# APM32F423 register map
File version: 1.0
CPU: CM4 r1p0, little endian, no MPU, no FPU, 4 interrupt priority bits
Registers are 32-bit, read-write, reset 0x0 unless marked. A register's access mark holds for its fields unless they carry their own. Offsets are from the block's base; [hi:lo] are bit positions.

## FMC — Flash memory controller
Base 0x40023C00
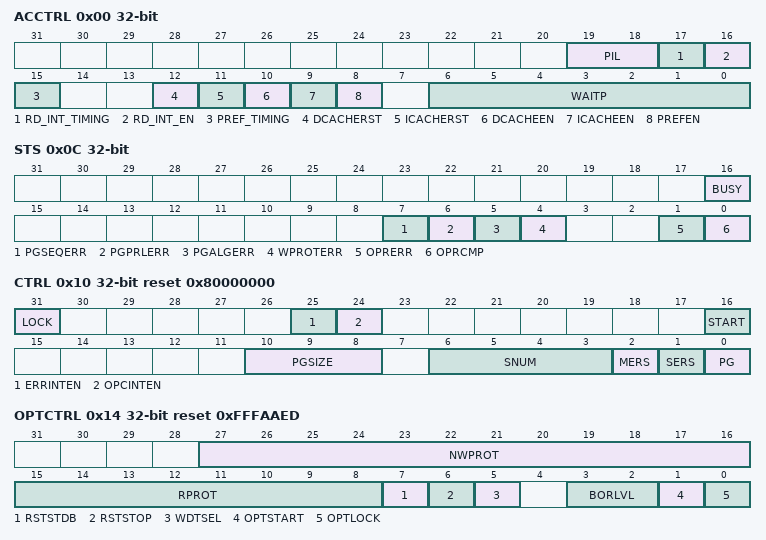
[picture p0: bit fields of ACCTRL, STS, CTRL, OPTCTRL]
0x00 ACCTRL — Flash access control register
  [19:18] PIL — Performance improve level performance
  [17] RD_INT_TIMING — Reading interrupts time control.
  [16] RD_INT_EN — Reading Interruption Control
  [15] PREF_TIMING — Prefetching strategy control.
  [12] DCACHERST — Data cache reset
  [11] ICACHERST — Instruction cache reset
  [10] DCACHEEN — Data cache enable
  [9] ICACHEEN — Instruction cache enable
  [8] PREFEN — Prefetch enable
  [6:0] WAITP — Wait Period
0x04 KEY wo — Flash key register
0x08 OPTKEY wo — Flash option key register
  [31:0] OPTKEY — Option byte key
0x0C STS access per field — Status register
  [16] BUSY ro
  [7] PGSEQERR rw — Programming sequence error
  [6] PGPRLERR rw — Programming parallelism error
  [5] PGALGERR rw — Programming alignment error
  [4] WPROTERR rw — Write protection error
  [1] OPRERR rw — Operation error
  [0] OPRCMP rw — End of operation
0x10 CTRL reset 0x80000000 — Control register
  [31] LOCK
  [25] ERRINTEN — Error interrupt enable
  [24] OPCINTEN — End of operation interrupt enable
  [16] START
  [10:8] PGSIZE — Program size
  [6:3] SNUM — Sector number
  [2] MERS — Mass Erase
  [1] SERS — Sector Erase
  [0] PG — Programming
0x14 OPTCTRL reset 0xFFFAAED — Flash option control register
  [27:16] NWPROT — Not write protect
  [15:8] RPROT — Read protect
  [7] RSTSTDB — nReset in STANDBY Mode
  [6] RSTSTOP — nRST_STOP User option mode
  [5] WDTSEL — Watchdog Select
  [3:2] BORLVL — Brownout reset Level
  [1] OPTSTART — Option start
  [0] OPTLOCK — Option lock

## QSPI — Quick Serial peripheral interface
Base 0xA0001000
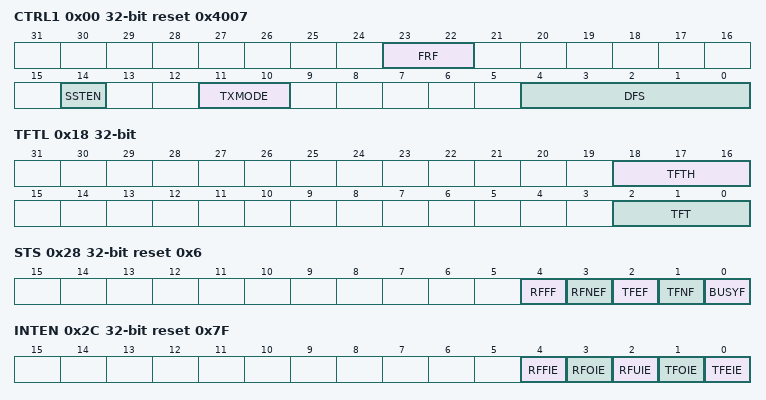
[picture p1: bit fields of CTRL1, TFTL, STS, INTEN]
0x00 CTRL1 reset 0x4007 — Control register 1
  [23:22] FRF, [14] SSTEN, [11:10] TXMODE, [4:0] DFS
0x04 CTRL2 — Control register 2
  [15:0] NDF
0x08 SSIEN — QSPI Enable register
  [0] EN
0x10 SLAEN — QSPI Slave enable register
  [0] SLAEN
0x14 BR — Baudrate register
  [15:0] CLKDIV
0x18 TFTL — Transmission FIFO threshhold level register
  [18:16] TFTH, [2:0] TFT
0x1C RFTL — Reception FIFO threshhold level register
  [2:0] RFT
0x20 TFL — Transmission FIFO level register
  [3:0] TFL
0x24 RFL — Reception FIFO level register
  [3:0] RFL
0x28 STS reset 0x6 — Status register
  [4] RFFF, [3] RFNEF, [2] TFEF, [1] TFNF, [0] BUSYF
0x2C INTEN reset 0x7F — Interrupt enable register
  [4] RFFIE, [3] RFOIE, [2] RFUIE, [1] TFOIE, [0] TFEIE
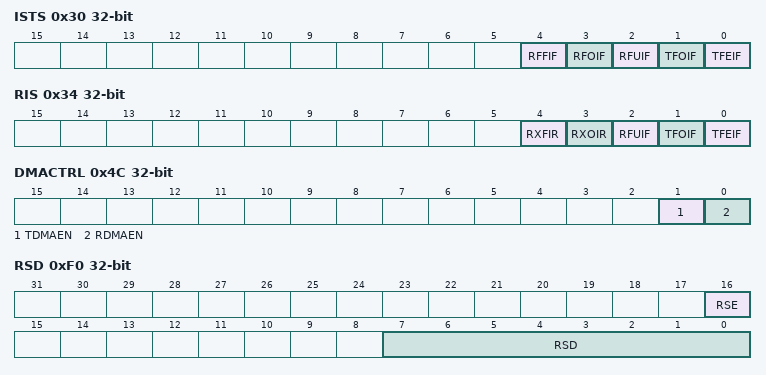
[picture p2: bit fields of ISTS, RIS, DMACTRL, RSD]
0x30 ISTS ro — Interrupt status register
  [4] RFFIF, [3] RFOIF, [2] RFUIF, [1] TFOIF, [0] TFEIF
0x34 RIS ro — Raw interrupt register
  [4] RXFIR, [3] RXOIR, [2] RFUIF, [1] TFOIF, [0] TFEIF
0x38 TFOIC ro — Transmission FIFO overflow interrupt clear register
  [0] TFOIC
0x3C RFOIC ro — Reception FIFO overflow interrupt clear register
  [0] RFOIC
0x40 RFUIC ro — Reception FIFO underflow interrupt clear register
  [0] RFUIC
0x48 ICF ro — Interrupt clear register
  [0] ICF
0x4C DMACTRL — dma control register
  [1] TDMAEN — Transmit DMA Enable
  [0] RDMAEN — Receive DMA Enable
0x50 DMATDL — dma tx data level register
  [2:0] DMATDL
0x54 DMARDL — dma rx data level register
  [2:0] DMARDL
0x60 DATA
0xF0 RSD — Reception sample register
  [16] RSE, [7:0] RSD
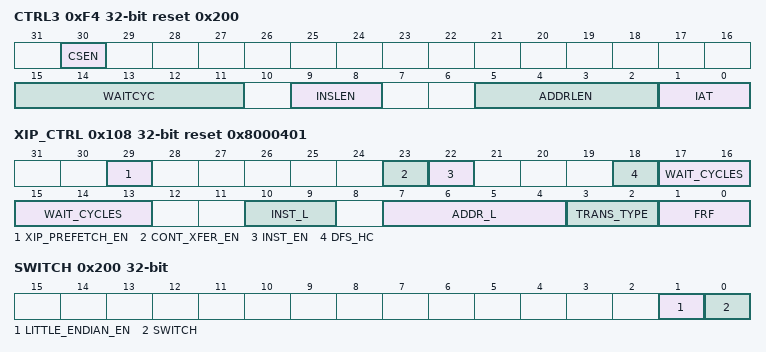
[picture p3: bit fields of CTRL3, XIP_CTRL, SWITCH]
0xF4 CTRL3 reset 0x200 — Control register 3
  [30] CSEN, [15:11] WAITCYC, [9:8] INSLEN, [5:2] ADDRLEN, [1:0] IAT
0x100 XIP_INCR_INST — XIP INCR transfer opcode register
  [15:0] INCR_INST
0x104 XIP_WRAP_INST — XIP_WRAP_INST transfer opcode register
  [15:0] WRAP_INST
0x108 XIP_CTRL reset 0x8000401 — XIP Control Register
  [29] XIP_PREFETCH_EN, [23] CONT_XFER_EN, [22] INST_EN, [18] DFS_HC, [17:13] WAIT_CYCLES, [10:9] INST_L, [7:4] ADDR_L, [3:2] TRANS_TYPE, [1:0] FRF
0x10C XIP_SER — Enable Register of the Machine
  [0] SER
0x200 SWITCH — IO switch register
  [1] LITTLE_ENDIAN_EN — Little endian enabled
  [0] SWITCH — I/O switch
0x204 XIP_EN — XIP Enable Register.
  [0] XIP_EN
